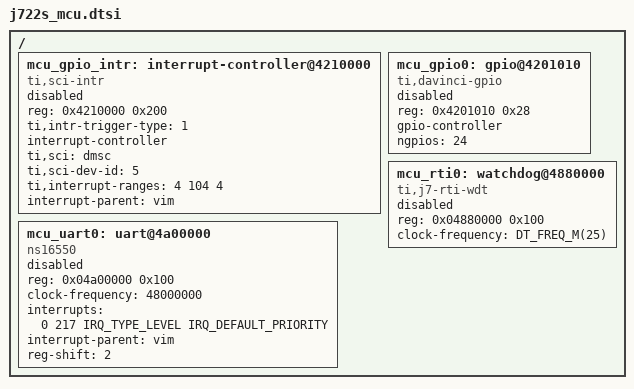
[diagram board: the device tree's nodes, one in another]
/*
 * Copyright (c) 2024 Texas Instruments Incorporated
 *	Andrew Davis <afd@ti.com>
 *
 * SPDX-License-Identifier: Apache-2.0
 */

#include <mem.h>
#include <freq.h>
#include <zephyr/dt-bindings/interrupt-controller/ti-vim.h>

/ {
	#address-cells = <1>;
	#size-cells = <1>;

	mcu_gpio_intr: interrupt-controller@4210000 {
		compatible = "ti,sci-intr";
		reg = <0x4210000 0x200>;
		ti,intr-trigger-type = <1>;
		interrupt-controller;
		#interrupt-cells = <1>;
		ti,sci = <&dmsc>;
		ti,sci-dev-id = <5>;
		/* R5-specific ti,interrupt-ranges set in main_r5 / mcu_r5 dtsi */
		ti,interrupt-ranges = <4 104 4>;
		interrupt-parent = <&vim>;
		status = "disabled";
	};

	mcu_gpio0: gpio@4201010 {
		compatible = "ti,davinci-gpio";
		reg = <0x4201010 0x28>;
		gpio-controller;
		#gpio-cells = <2>;
		ngpios = <24>;
		status = "disabled";
	};

	mcu_uart0: uart@4a00000 {
		compatible = "ns16550";
		reg = <0x04a00000 0x100>;
		clock-frequency = <48000000>;
		interrupts = <0 217 IRQ_TYPE_LEVEL IRQ_DEFAULT_PRIORITY>;
		interrupt-parent = <&vim>;
		reg-shift = <2>;
		status = "disabled";
	};

	mcu_rti0: watchdog@4880000 {
		compatible = "ti,j7-rti-wdt";
		reg = <0x04880000 0x100>;
		clock-frequency = <DT_FREQ_M(25)>;
		status = "disabled";
	};
};
